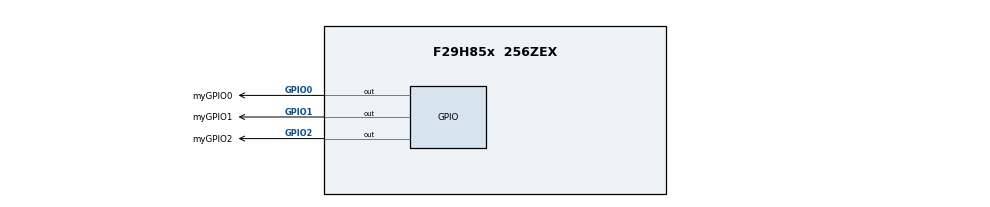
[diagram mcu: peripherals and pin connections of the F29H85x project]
/**
 * @cliArgs --device "F29H85x" --package "256ZEX" --part "F29H85x_256ZEX" --context "CPU1" --product "MCU_SDK_F29H85x@1.00.00.00"
 * @versions {"tool":"1.22.0+3877"}
 */

const divider15       = system.clockTree["PLL_REFDIV"];
divider15.divideValue = 1;

const multiplier1         = system.clockTree["PLL_IMULT"];
multiplier1.multiplyValue = 40;

const mux7       = system.clockTree["OSCCLKSRCSEL"];
mux7.inputSelect = "INTOSC2";

/**
 * Import the modules used in this configuration.
 */

const gpio             = scripting.addModule("/driverlib/gpio.js", {}, false);
const gpio1            = gpio.addInstance();
const gpio2            = gpio.addInstance();
const gpio3            = gpio.addInstance();
const inputxbar_input  = scripting.addModule("/driverlib/inputxbar_input.js", {}, false);
const inputxbar_input1 = inputxbar_input.addInstance();
const jtag             = scripting.addModule("/driverlib/jtag.js");

/**
 * Write custom configuration values to the imported modules.
 */
gpio1.$name                      = "myGPIO0";
gpio1.useInterrupt               = true;
gpio1.gpioPin.$assign            = "GPIO0";
gpio1.xint.registerInterrupts    = true;
gpio1.xint.enableInt             = true;
gpio1.xint.xInt.interruptHandler = "XINT1_ISR";

gpio2.$name           = "myGPIO1";
gpio2.direction       = "GPIO_DIR_MODE_OUT";
gpio2.gpioPin.$assign = "GPIO1";

gpio3.$name           = "myGPIO2";
gpio3.direction       = "GPIO_DIR_MODE_OUT";
gpio3.gpioPin.$assign = "GPIO2";

inputxbar_input1.$name         = "myINPUTXBARINPUT0";
gpio1.xint.inputxbar           = inputxbar_input1;
inputxbar_input1.inputxbarGpio = "GPIO0";
